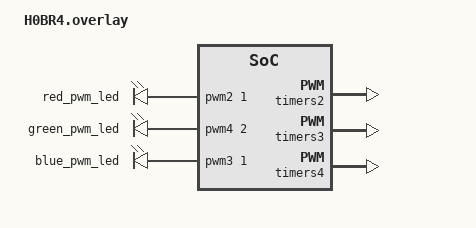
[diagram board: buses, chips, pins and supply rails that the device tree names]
/*
 Timer for RGB red - PA15    ------> TIM2_CH1
 Timer for RGB blue - PA6    ------> TIM3_CH1
 Timer for RGB green - PB7   ------> TIM4_CH2
 */

/ {

	/* pwmleds Node: This node defines the configuration for PWM-controlled LEDs. */
	 pwmleds {
		compatible = "pwm-leds";
		status = "okay";

		/* Sub-Node: */
		red_pwm_led: red_pwm_led {
			/* &pwm2: References the pwm3 controller node.
			 * 1: The PWM channel number.
			 * PWM_MSEC(20): The period of the PWM signal in milliseconds (20 ms in this case).
			 * PWM_POLARITY_NORMAL: Indicates the polarity of the PWM signal. */
			pwms = <&pwm2 1 PWM_MSEC(20) PWM_POLARITY_NORMAL>;
		};
		green_pwm_led: green_pwm_led {
			pwms = <&pwm4 2 PWM_MSEC(20) PWM_POLARITY_NORMAL>;
		};
		blue_pwm_led: blue_pwm_led {
			pwms = <&pwm3 1 PWM_MSEC(20) PWM_POLARITY_NORMAL>;
		};
	};

	aliases {
		red-pwm-led = &red_pwm_led;
		green-pwm-led = &green_pwm_led;
		blue-pwm-led = &blue_pwm_led;
	};

};


&timers2 {
	st,prescaler = <10000>;
	status = "okay";
	pwm2: pwm {
		status = "okay";
		pinctrl-0 = <&tim2_ch1_pa15>;
		pinctrl-names = "default";
	};
};

&timers3 {
	st,prescaler = <10000>;
	status = "okay";
	pwm3: pwm {
		status = "okay";
		pinctrl-0 = <&tim3_ch1_pa6>;
		pinctrl-names = "default";
	};
};

&timers4 {
	st,prescaler = <10000>;
	status = "okay";
	pwm4: pwm {
		status = "okay";
		pinctrl-0 = <&tim4_ch2_pb7>;
		pinctrl-names = "default";
	};
};
